# STM32G07x register map
File version: 1.3
CPU: CM0+ r0p0, little endian, no MPU, no FPU, 3 interrupt priority bits
Registers are 32-bit, read-write, reset 0x0 unless marked. A register's access mark holds for its fields unless they carry their own. Offsets are from the block's base; [hi:lo] are bit positions.

## UCPD1 — USB Power Delivery interface
Base 0x4000A000
Same registers: UCPD2 0x4000A400
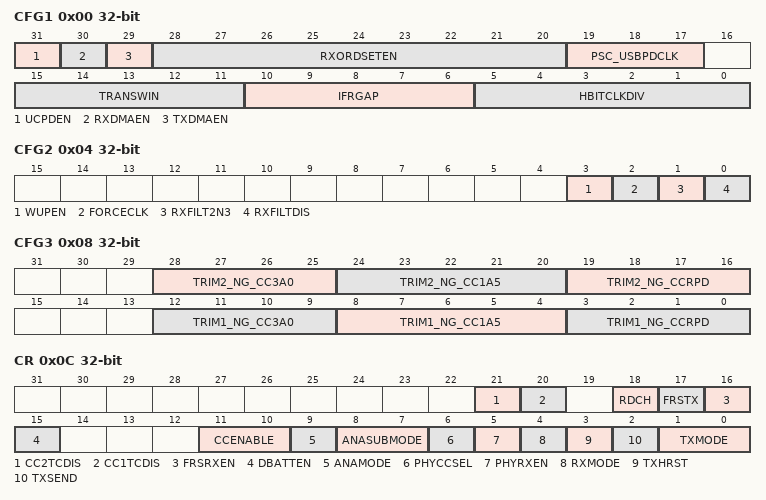
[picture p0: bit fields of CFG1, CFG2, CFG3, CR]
0x00 CFG1 — UCPD configuration register
  [31] UCPDEN, [30] RXDMAEN, [29] TXDMAEN, [28:20] RXORDSETEN, [19:17] PSC_USBPDCLK, [15:11] TRANSWIN, [10:6] IFRGAP, [5:0] HBITCLKDIV
0x04 CFG2 — UCPD configuration register 2
  [3] WUPEN, [2] FORCECLK, [1] RXFILT2N3, [0] RXFILTDIS
0x08 CFG3 — UCPD configuration register 3
  [28:25] TRIM2_NG_CC3A0, [24:20] TRIM2_NG_CC1A5, [19:16] TRIM2_NG_CCRPD, [12:9] TRIM1_NG_CC3A0, [8:4] TRIM1_NG_CC1A5, [3:0] TRIM1_NG_CCRPD
0x0C CR — UCPD control register
  [21] CC2TCDIS, [20] CC1TCDIS, [18] RDCH, [17] FRSTX, [16] FRSRXEN, [15] DBATTEN, [11:10] CCENABLE, [9] ANAMODE, [8:7] ANASUBMODE, [6] PHYCCSEL, [5] PHYRXEN, [4] RXMODE, [3] TXHRST, [2] TXSEND, [1:0] TXMODE
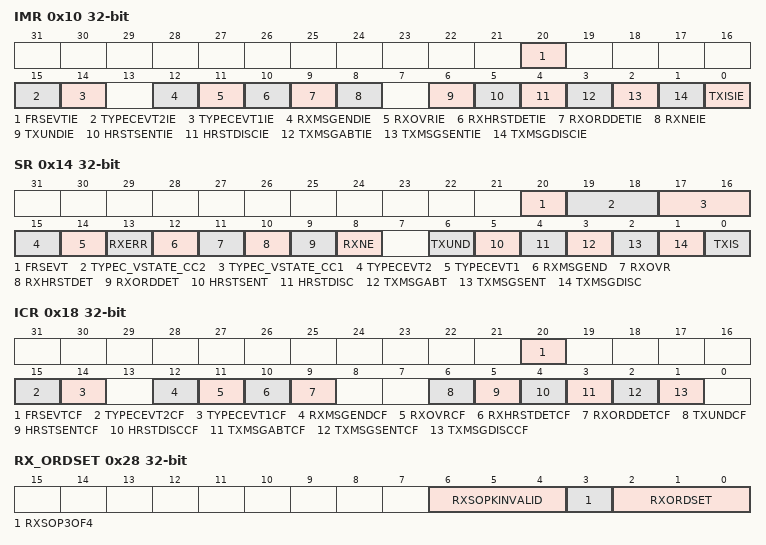
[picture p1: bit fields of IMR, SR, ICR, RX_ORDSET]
0x10 IMR — UCPD Interrupt Mask Register
  [20] FRSEVTIE, [15] TYPECEVT2IE, [14] TYPECEVT1IE, [12] RXMSGENDIE, [11] RXOVRIE, [10] RXHRSTDETIE, [9] RXORDDETIE, [8] RXNEIE, [6] TXUNDIE, [5] HRSTSENTIE, [4] HRSTDISCIE, [3] TXMSGABTIE, [2] TXMSGSENTIE, [1] TXMSGDISCIE, [0] TXISIE
0x14 SR ro — UCPD Status Register
  [20] FRSEVT, [19:18] TYPEC_VSTATE_CC2, [17:16] TYPEC_VSTATE_CC1, [15] TYPECEVT2, [14] TYPECEVT1, [13] RXERR, [12] RXMSGEND, [11] RXOVR, [10] RXHRSTDET, [9] RXORDDET, [8] RXNE, [6] TXUND, [5] HRSTSENT, [4] HRSTDISC, [3] TXMSGABT, [2] TXMSGSENT, [1] TXMSGDISC, [0] TXIS
0x18 ICR — UCPD Interrupt Clear Register
  [20] FRSEVTCF, [15] TYPECEVT2CF, [14] TYPECEVT1CF, [12] RXMSGENDCF, [11] RXOVRCF, [10] RXHRSTDETCF, [9] RXORDDETCF, [6] TXUNDCF, [5] HRSTSENTCF, [4] HRSTDISCCF, [3] TXMSGABTCF, [2] TXMSGSENTCF, [1] TXMSGDISCCF
0x1C TX_ORDSET — UCPD Tx Ordered Set Type Register
  [19:0] TXORDSET
0x20 TX_PAYSZ — UCPD Tx Paysize Register
  [9:0] TXPAYSZ
0x24 TXDR — UCPD Tx Data Register
  [7:0] TXDATA
0x28 RX_ORDSET ro — UCPD Rx Ordered Set Register
  [6:4] RXSOPKINVALID, [3] RXSOP3OF4, [2:0] RXORDSET
0x2C RX_PAYSZ — UCPD Rx Paysize Register
  [9:0] RXPAYSZ
0x30 RXDR ro — UCPD Receive Data Register
  [7:0] RXDATA
0x34 RX_ORDEXT1 — UCPD Rx Ordered Set Extension Register
  [19:0] RXSOPX1
0x38 RX_ORDEXT2 — UCPD Rx Ordered Set Extension Register
  [19:0] RXSOPX2
0x3F4 IPVER ro reset 0x10 — UCPD IP ID register
0x3F8 IPID ro reset 0x150021 — UCPD IP ID register
0x3FC MID ro reset 0xA3C5DD01 — UCPD IP ID register
  [31:0] IPID

## LPTIM1 — Low power timer
Base 0x40007C00
Same registers: LPTIM2 0x40009400
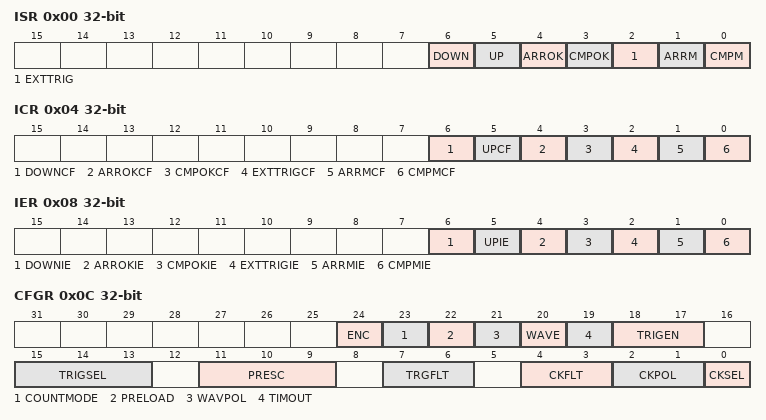
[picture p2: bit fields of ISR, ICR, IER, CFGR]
0x00 ISR ro — Interrupt and Status Register
  [6] DOWN — Counter direction change up to down
  [5] UP — Counter direction change down to up
  [4] ARROK — Autoreload register update OK
  [3] CMPOK — Compare register update OK
  [2] EXTTRIG — External trigger edge event
  [1] ARRM — Autoreload match
  [0] CMPM — Compare match
0x04 ICR wo — Interrupt Clear Register
  [6] DOWNCF — Direction change to down Clear Flag
  [5] UPCF — Direction change to UP Clear Flag
  [4] ARROKCF — Autoreload register update OK Clear Flag
  [3] CMPOKCF — Compare register update OK Clear Flag
  [2] EXTTRIGCF — External trigger valid edge Clear Flag
  [1] ARRMCF — Autoreload match Clear Flag
  [0] CMPMCF — compare match Clear Flag
0x08 IER — Interrupt Enable Register
  [6] DOWNIE — Direction change to down Interrupt Enable
  [5] UPIE — Direction change to UP Interrupt Enable
  [4] ARROKIE — Autoreload register update OK Interrupt Enable
  [3] CMPOKIE — Compare register update OK Interrupt Enable
  [2] EXTTRIGIE — External trigger valid edge Interrupt Enable
  [1] ARRMIE — Autoreload match Interrupt Enable
  [0] CMPMIE — Compare match Interrupt Enable
0x0C CFGR — Configuration Register
  [24] ENC — Encoder mode enable
  [23] COUNTMODE — counter mode enabled
  [22] PRELOAD — Registers update mode
  [21] WAVPOL — Waveform shape polarity
  [20] WAVE — Waveform shape
  [19] TIMOUT — Timeout enable
  [18:17] TRIGEN — Trigger enable and polarity
  [15:13] TRIGSEL — Trigger selector
  [11:9] PRESC — Clock prescaler
  [7:6] TRGFLT — Configurable digital filter for trigger
  [4:3] CKFLT — Configurable digital filter for external clock
  [2:1] CKPOL — Clock Polarity
  [0] CKSEL — Clock selector
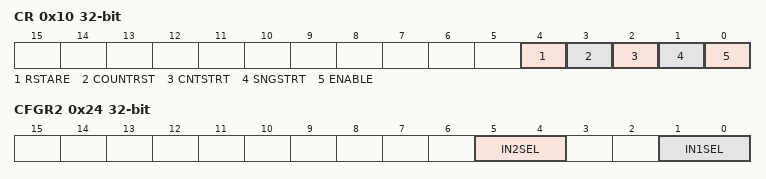
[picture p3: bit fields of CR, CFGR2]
0x10 CR — Control Register
  [4] RSTARE — Reset after read enable
  [3] COUNTRST — Counter reset
  [2] CNTSTRT — Timer start in continuous mode
  [1] SNGSTRT — LPTIM start in single mode
  [0] ENABLE — LPTIM Enable
0x14 CMP — Compare Register
  [15:0] CMP — Compare value
0x18 ARR reset 0x1 — Autoreload Register
  [15:0] ARR — Auto reload value
0x1C CNT ro — Counter Register
  [15:0] CNT — Counter value
0x24 CFGR2 — LPTIM configuration register 2
  [5:4] IN2SEL — LPTIM1 Input 2 selection
  [1:0] IN1SEL — LPTIMx Input 1 selection
